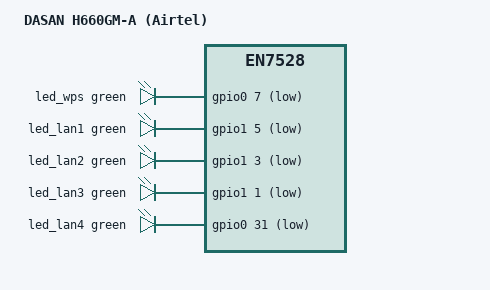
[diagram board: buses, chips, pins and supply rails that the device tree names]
// SPDX-License-Identifier: (GPL-2.0-only OR BSD-2-Clause)
/dts-v1/;

#include "en7528_dasan_h660gm-a.dtsi"

/ {
	model = "DASAN H660GM-A (Airtel)";
	compatible = "dasan,h660gm-a-airtel", "econet,en7528";

	leds {
		led_wps: wps {
			color = <LED_COLOR_ID_GREEN>;
			function = LED_FUNCTION_WPS;
			gpios = <&gpio0 7 GPIO_ACTIVE_LOW>;
		};

		led_lan1: lan1 {
			color = <LED_COLOR_ID_GREEN>;
			function = LED_FUNCTION_LAN;
			function-enumerator = <1>;
			gpios = <&gpio1 5 GPIO_ACTIVE_LOW>;
		};

		led_lan2: lan2 {
			color = <LED_COLOR_ID_GREEN>;
			function = LED_FUNCTION_LAN;
			function-enumerator = <2>;
			gpios = <&gpio1 3 GPIO_ACTIVE_LOW>;
		};

		led_lan3: lan3 {
			color = <LED_COLOR_ID_GREEN>;
			function = LED_FUNCTION_LAN;
			function-enumerator = <3>;
			gpios = <&gpio1 1 GPIO_ACTIVE_LOW>;
		};

		led_lan4: lan4 {
			color = <LED_COLOR_ID_GREEN>;
			function = LED_FUNCTION_LAN;
			function-enumerator = <4>;
			gpios = <&gpio0 31 GPIO_ACTIVE_LOW>;
		};
	};
};

&partitions {
	/* Concatenated with tclinux_rootfs to form the UBI volume */
	root1: partition@60c0000 {
		label = "unknown";
		reg = <0x60c0000 0x7d00000>;
	};

	partition@ddc0000 {
		label = "reservearea";
		reg = <0xddc0000 0x240000>;
		nvmem-layout {
			compatible = "fixed-layout";
			#address-cells = <1>;
			#size-cells = <1>;

			eeprom_reservearea_40000: eeprom@40000 {
				reg = <0x40000 0x4da8>;
			};

			eeprom_reservearea_1c0000: eeprom@1c0000 {
				reg = <0x1c0000 0x400>;
			};
		};
	};
};

/* Sockets are numbered in switch port order: LAN1 is port 1. */
&gsw_port1 {
	label = "lan1";
};

&gsw_port2 {
	label = "lan2";
};

&gsw_port3 {
	label = "lan3";
};

&gsw_port4 {
	label = "lan4";
};
